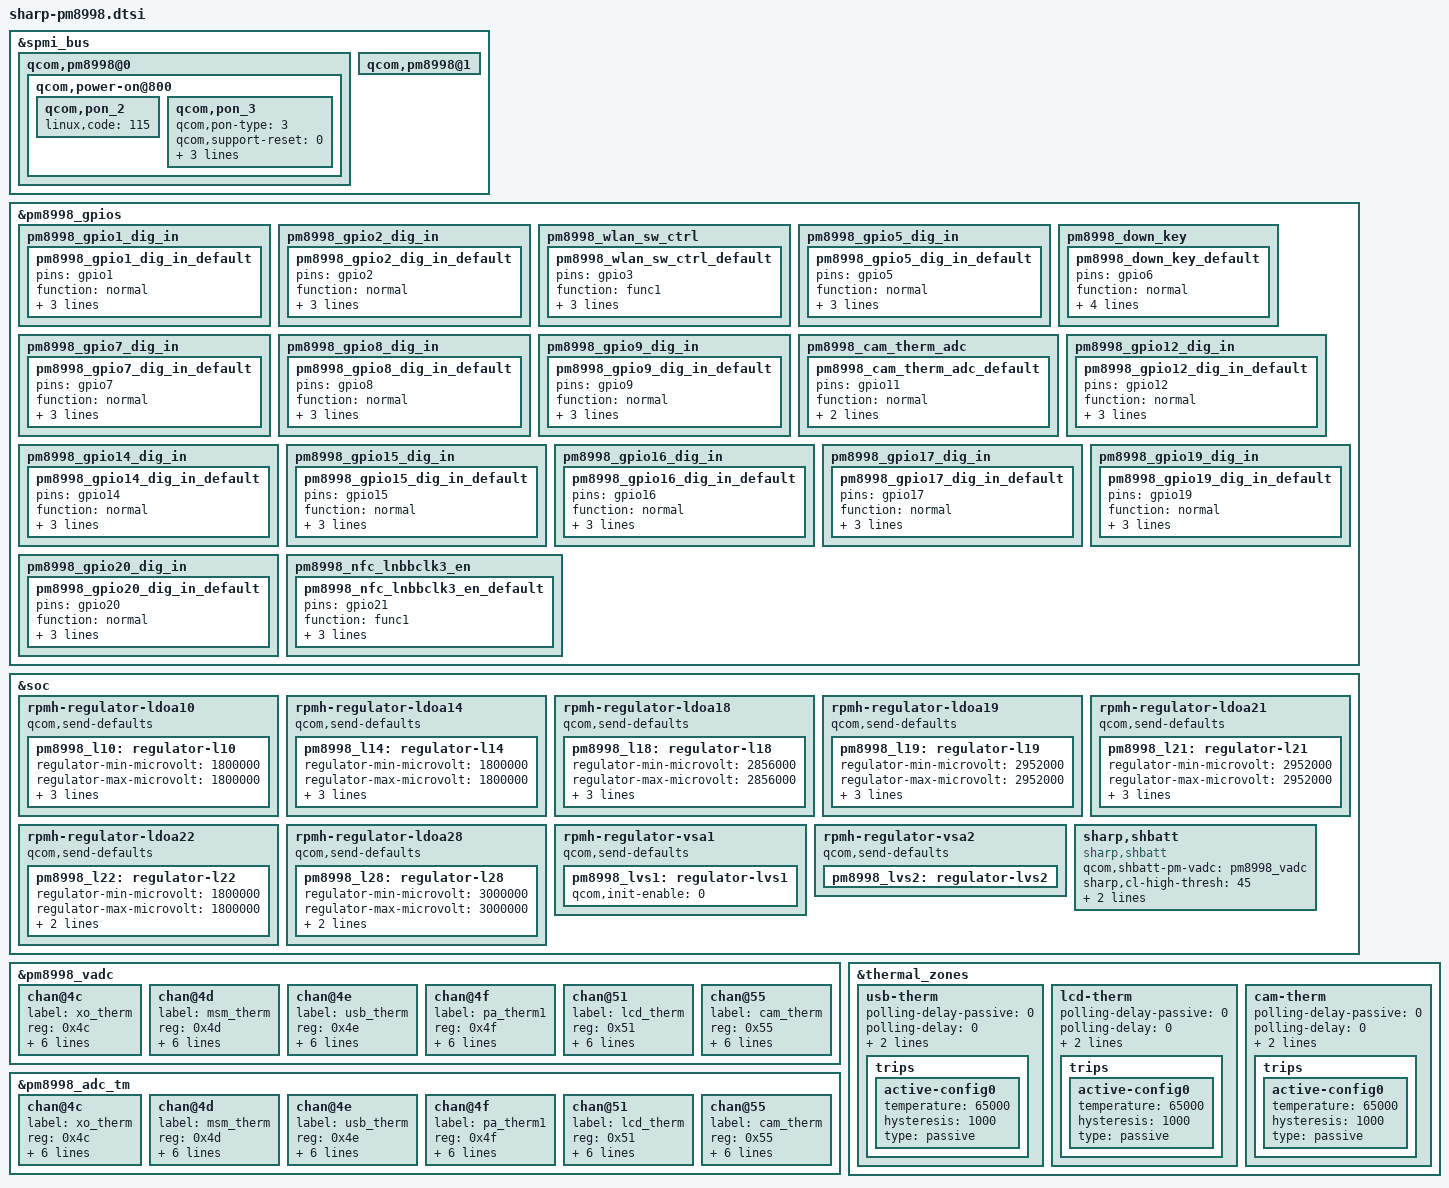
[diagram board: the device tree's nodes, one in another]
/* Copyright (c) 2014-2015, The Linux Foundation. All rights reserved.
 *
 * This program is free software; you can redistribute it and/or modify
 * it under the terms of the GNU General Public License version 2 and
 * only version 2 as published by the Free Software Foundation.
 *
 * This program is distributed in the hope that it will be useful,
 * but WITHOUT ANY WARRANTY; without even the implied warranty of
 * MERCHANTABILITY or FITNESS FOR A PARTICULAR PURPOSE.  See the
 * GNU General Public License for more details.
 */
#include <dt-bindings/gpio/gpio.h>
#include <dt-bindings/regulator/qcom,rpmh-regulator.h>

/*****************************************/
/*  pm8998: qcom,pm8998 alias            */
/*****************************************/

&spmi_bus {
	qcom,pm8998@0 {
		qcom,power-on@800 {
			qcom,pon_2 {
				linux,code = <115>;
			};
			qcom,pon_3 {
				qcom,pon-type = <3>;
				qcom,support-reset = <0>;
				qcom,pull-up = <1>;
				qcom,s1-timer = <6720>;
				qcom,s2-timer = <2000>;
			};
		};
	};

	qcom,pm8998@1 {
	};
};

/*****************************************/
/*  pm8998-gpios: qpnp-pin               */
/*****************************************/

&pm8998_gpios {
//	compatible = "qcom,spmi-gpio";
//	reg = <0xc000 0x1a00>;
//	interrupts = <0x0 0xc0 0 IRQ_TYPE_NONE>,
//			<0x0 0xc1 0 IRQ_TYPE_NONE>,
//			<0x0 0xc2 0 IRQ_TYPE_NONE>,
//			<0x0 0xc3 0 IRQ_TYPE_NONE>,
//			<0x0 0xc4 0 IRQ_TYPE_NONE>,
//			<0x0 0xc5 0 IRQ_TYPE_NONE>,
//			<0x0 0xc6 0 IRQ_TYPE_NONE>,
//			<0x0 0xc7 0 IRQ_TYPE_NONE>,
//			<0x0 0xc8 0 IRQ_TYPE_NONE>,
//			<0x0 0xc9 0 IRQ_TYPE_NONE>,
//			<0x0 0xca 0 IRQ_TYPE_NONE>,
//			<0x0 0xcb 0 IRQ_TYPE_NONE>,
//			<0x0 0xcc 0 IRQ_TYPE_NONE>,
//			<0x0 0xcd 0 IRQ_TYPE_NONE>,
//			<0x0 0xce 0 IRQ_TYPE_NONE>,
//			<0x0 0xcf 0 IRQ_TYPE_NONE>,
//			<0x0 0xd0 0 IRQ_TYPE_NONE>,
//			<0x0 0xd1 0 IRQ_TYPE_NONE>,
//			<0x0 0xd2 0 IRQ_TYPE_NONE>,
//			<0x0 0xd3 0 IRQ_TYPE_NONE>,
//			<0x0 0xd4 0 IRQ_TYPE_NONE>,
//			<0x0 0xd5 0 IRQ_TYPE_NONE>,
//			<0x0 0xd6 0 IRQ_TYPE_NONE>;
//	interrupt-names = "pm8998_gpio1", "pm8998_gpio2",
//			"pm8998_gpio3", "pm8998_gpio4",
//			"pm8998_gpio5", "pm8998_gpio6",
//			"pm8998_gpio7", "pm8998_gpio8",
//			"pm8998_gpio9", "pm8998_gpio10",
//			"pm8998_gpio11", "pm8998_gpio12",
//			"pm8998_gpio13", "pm8998_gpio14",
//			"pm8998_gpio15", "pm8998_gpio16",
//			"pm8998_gpio17", "pm8998_gpio18",
//			"pm8998_gpio19", "pm8998_gpio20",
//			"pm8998_gpio21", "pm8998_gpio22",
//			"pm8998_gpio23";
//	gpio-controller;
//	#gpio-cells = <2>;
//	qcom,gpios-disallowed = <24 25 26>;

//	pinctrl-names = "default";
//	pinctrl-0 = <&pm8998_gpio1_dig_in_default
//				&pm8998_gpio2_dig_in_default
//				&pm8998_wlan_sw_ctrl_default
//				&pm8998_gpio5_dig_in_default
//				&pm8998_down_key_default
//				&pm8998_gpio7_dig_in_default
//				&pm8998_gpio8_dig_in_default
//				&pm8998_gpio9_dig_in_default
//				&pm8998_sd_pow_en_default
//				&pm8998_cam_therm_adc_default
//				&pm8998_gpio12_dig_in_default
//				&pm8998_lcd_clk_default
//				&pm8998_gpio14_dig_in_default
//				&pm8998_gpio15_dig_in_default
//				&pm8998_gpio16_dig_in_default
//				&pm8998_gpio17_dig_in_default
//				&pm8998_gpio18_dig_in_default
//				&pm8998_gpio19_dig_in_default
//				&pm8998_gpio20_dig_in_default
//				&pm8998_nfc_lnbbclk3_en_default
//				&pm8998_gpio22_dig_in_default>;

	pm8998_gpio1_dig_in {
		/* I/PD/L */	/* - */
		pm8998_gpio1_dig_in_default: pm8998_gpio1_dig_in_default {
			pins = "gpio1";			/* GPIO 1 */
			function = "normal";	/* normal input */
			bias-pull-down;			/* pull down */
			power-source = <0>;		/* VIN0 */
			input-enable;			/* digital input */
		};
	};

	pm8998_gpio2_dig_in {
		/* I/PD/L */	/* - */
		pm8998_gpio2_dig_in_default: pm8998_gpio2_dig_in_default {
			pins = "gpio2";			/* GPIO 2 */
			function = "normal";	/* normal input */
			bias-pull-down;			/* pull down */
			power-source = <0>;		/* VIN0 */
			input-enable;			/* digital input */
		};
	};

	pm8998_wlan_sw_ctrl {
		/* I/PD/L */	/* WLAN_SW_CTRL */
		pm8998_wlan_sw_ctrl_default: pm8998_wlan_sw_ctrl_default {
			pins = "gpio3";			/* GPIO 3 */
			function = "func1";		/* Special Function 1 */
			bias-pull-down;			/* pull down */
			power-source = <0>;		/* VIN0 */
			input-enable;			/* digital input */
		};
	};

	pm8998_gpio5_dig_in {
		/* I/PD/L */	/* - */
		pm8998_gpio5_dig_in_default: pm8998_gpio5_dig_in_default {
			pins = "gpio5";			/* GPIO 5 */
			function = "normal";	/* normal input */
			bias-pull-down;			/* pull down */
			power-source = <0>;		/* VIN0 */
			input-enable;			/* digital input */
		};
	};

	pm8998_down_key {
		/* I/PU,30uA/H */	/* DOWN_KEY */
		pm8998_down_key_default: pm8998_down_key_default {
			pins = "gpio6";					/* GPIO 6 */
			function = "normal";			/* normal input */
			bias-pull-up;					/* enable pull up */
			qcom,pull-up-strength = <0>;	/* 30uA pull up */
			power-source = <0>;				/* VIN0 */
			input-enable;					/* digital input */
		};
	};

	pm8998_gpio7_dig_in {
		/* I/PD/L */	/* - */
		pm8998_gpio7_dig_in_default: pm8998_gpio7_dig_in_default {
			pins = "gpio7";			/* GPIO 7 */
			function = "normal";	/* normal input */
			bias-pull-down;			/* pull down */
			power-source = <0>;		/* VIN0 */
			input-enable;			/* digital input */
		};
	};

	pm8998_gpio8_dig_in {
		/* I/PD/L */	/* - */
		pm8998_gpio8_dig_in_default: pm8998_gpio8_dig_in_default {
			pins = "gpio8";			/* GPIO 8 */
			function = "normal";	/* normal input */
			bias-pull-down;			/* pull down */
			power-source = <0>;		/* VIN0 */
			input-enable;			/* digital input */
		};
	};

	pm8998_gpio9_dig_in {
		/* I/PD/L */	/* - */
		pm8998_gpio9_dig_in_default: pm8998_gpio9_dig_in_default {
			pins = "gpio9";			/* GPIO 9 */
			function = "normal";	/* normal input */
			bias-pull-down;			/* pull down */
			power-source = <0>;		/* VIN0 */
			input-enable;			/* digital input */
		};
	};

	pm8998_cam_therm_adc {
		/* I/-/Z */	/* CAM_THERM */
		pm8998_cam_therm_adc_default: pm8998_cam_therm_adc_default {
			pins = "gpio11";		/* GPIO 11 */
			function = "normal";	/* normal */
			bias-high-impedance;	/* DISABLE GPIO11 for ADC*/
			qcom,drive-strength = <1>;	/* Low strength */
		};
	};

	pm8998_gpio12_dig_in {
		/* I/PD/L */	/* - */
		pm8998_gpio12_dig_in_default: pm8998_gpio12_dig_in_default {
			pins = "gpio12";		/* GPIO 12 */
			function = "normal";	/* normal input */
			bias-pull-down;			/* pull down */
			power-source = <0>;		/* VIN0 */
			input-enable;			/* digital input */
		};
	};

	pm8998_gpio14_dig_in {
		/* I/PD/L */	/* - */
		pm8998_gpio14_dig_in_default: pm8998_gpio14_dig_in_default {
			pins = "gpio14";		/* GPIO 14 */
			function = "normal";	/* normal input */
			bias-pull-down;			/* pull down */
			power-source = <0>;		/* VIN0 */
			input-enable;			/* digital input */
		};
	};

	pm8998_gpio15_dig_in {
		/* I/PD/L */	/* - */
		pm8998_gpio15_dig_in_default: pm8998_gpio15_dig_in_default {
			pins = "gpio15";		/* GPIO 15 */
			function = "normal";	/* normal input */
			bias-pull-down;			/* pull down */
			power-source = <0>;		/* VIN0 */
			input-enable;			/* digital input */
		};
	};

	pm8998_gpio16_dig_in {
		/* I/PD/L */	/* - */
		pm8998_gpio16_dig_in_default: pm8998_gpio16_dig_in_default {
			pins = "gpio16";		/* GPIO 16 */
			function = "normal";	/* normal input */
			bias-pull-down;			/* pull down */
			power-source = <0>;		/* VIN0 */
			input-enable;			/* digital input */
		};
	};

	pm8998_gpio17_dig_in {
		/* I/PD/L */	/* - */
		pm8998_gpio17_dig_in_default: pm8998_gpio17_dig_in_default {
			pins = "gpio17";		/* GPIO 17 */
			function = "normal";	/* normal input */
			bias-pull-down;			/* pull down */
			power-source = <0>;		/* VIN0 */
			input-enable;			/* digital input */
		};
	};

	pm8998_gpio19_dig_in {
		/* I/PD/L */	/* - */
		pm8998_gpio19_dig_in_default: pm8998_gpio19_dig_in_default {
			pins = "gpio19";		/* GPIO 19 */
			function = "normal";	/* normal input */
			bias-pull-down;			/* pull down */
			power-source = <1>;		/* VIN1 */
			input-enable;			/* digital input */
		};
	};

	pm8998_gpio20_dig_in {
		/* I/PD/L */	/* - */
		pm8998_gpio20_dig_in_default: pm8998_gpio20_dig_in_default {
			pins = "gpio20";		/* GPIO 20 */
			function = "normal";	/* normal input */
			bias-pull-down;			/* pull down */
			power-source = <1>;		/* VIN1 */
			input-enable;			/* digital input */
		};
	};

	pm8998_nfc_lnbbclk3_en {
		/* I/NP/L */	/* NFC_LNBBCLK3_EN */
		pm8998_nfc_lnbbclk3_en_default: pm8998_nfc_lnbbclk3_en_default {
			pins = "gpio21";		/* GPIO 21 */
			function = "func1";		/* Special Function 1 */
			bias-pull-down;			/* pull down */
			power-source = <1>;		/* VIN1 */
			input-enable;			/* digital input */
		};
	};
};

/*****************************************/
/*  pm8998: rpm-regulator              */
/*****************************************/
&soc {
	rpmh-regulator-ldoa10 {
		qcom,send-defaults;
		pm8998_l10: regulator-l10 {	/* SIM2 */
			regulator-min-microvolt = <1800000>;
			regulator-max-microvolt = <1800000>;
			qcom,init-voltage = <1800000>;
			qcom,init-mode = <RPMH_REGULATOR_MODE_LPM>;
			qcom,init-enable = <0>;
		};
	};

	rpmh-regulator-ldoa14 {
		qcom,send-defaults;
		pm8998_l14: regulator-l14 {	/* LCD driver digital */
			regulator-min-microvolt = <1800000>;
			regulator-max-microvolt = <1800000>;
			qcom,init-voltage = <1800000>;
			qcom,init-mode = <RPMH_REGULATOR_MODE_HPM>;
			qcom,init-enable = <1>;
		};
	};

	rpmh-regulator-ldoa18 {
		qcom,send-defaults;
		pm8998_l18: regulator-l18 {	/* DTV LNA */
			regulator-min-microvolt = <2856000>;
			regulator-max-microvolt = <2856000>;
			qcom,init-voltage = <2856000>;
			qcom,init-mode = <RPMH_REGULATOR_MODE_HPM>;
			qcom,init-enable = <0>;
		};
	};

	rpmh-regulator-ldoa19 {
		qcom,send-defaults;
		pm8998_l19: regulator-l19 {	/* Proximity */
			regulator-min-microvolt = <2952000>;
			regulator-max-microvolt = <2952000>;
			qcom,init-voltage = <2952000>;
			qcom,init-mode = <RPMH_REGULATOR_MODE_LPM>;
			qcom,init-enable = <0>;
		};
	};

	rpmh-regulator-ldoa21 {
		qcom,send-defaults;
		pm8998_l21: regulator-l21 {	/* Camera AF driver */
			regulator-min-microvolt = <2952000>;
			regulator-max-microvolt = <2952000>;
			qcom,init-voltage = <2952000>;
			qcom,init-mode = <RPMH_REGULATOR_MODE_HPM>;
			qcom,init-enable = <0>;
		};
	};

	rpmh-regulator-ldoa22 {
//		qcom,use-awake-state;
		qcom,send-defaults;
		pm8998_l22: regulator-l22 {	/* Fingerprint */
			regulator-min-microvolt = <1800000>;
			regulator-max-microvolt = <1800000>;
			qcom,init-voltage = <1800000>;
			qcom,init-enable = <0>;
		};
	};

	rpmh-regulator-ldoa28 {
		qcom,send-defaults;
		pm8998_l28: regulator-l28 {	/* Touch panel analog */
			regulator-min-microvolt = <3000000>;
			regulator-max-microvolt = <3000000>;
			qcom,init-voltage = <3000000>;
			qcom,init-mode = <RPMH_REGULATOR_MODE_HPM>;
			/delete-property/ qcom,init-enable;
		};
	};

	rpmh-regulator-vsa1 {
		qcom,send-defaults;
		pm8998_lvs1: regulator-lvs1 {	/* Camera IO */
			qcom,init-enable = <0>;
		};
	};

	rpmh-regulator-vsa2 {
		qcom,send-defaults;
		pm8998_lvs2: regulator-lvs2 {	/* Touch panel digital and /IO */
			/delete-property/ qcom,init-enable;
		};
	};
};
/*****************************************/
/*  qpnp-adc-voltage                     */
/*****************************************/
&pm8998_vadc {
	chan@4c { /* xo_therm */
		label = "xo_therm";
		reg = <0x4c>;
		qcom,decimation = <2>;
		qcom,pre-div-channel-scaling = <0>;
		qcom,calibration-type = "ratiometric";
		qcom,scale-function = <4>;
		qcom,hw-settle-time = <2>;
		qcom,fast-avg-setup = <0>;
	};

	chan@4d { /* msm_therm */
		label = "msm_therm";
		reg = <0x4d>;
		qcom,decimation = <2>;
		qcom,pre-div-channel-scaling = <0>;
		qcom,calibration-type = "ratiometric";
		qcom,scale-function = <2>;
		qcom,hw-settle-time = <2>;
		qcom,fast-avg-setup = <0>;
	};

	chan@4e { /* usb_therm */
		label = "usb_therm";
		reg = <0x4e>;
		qcom,decimation = <2>;
		qcom,pre-div-channel-scaling = <0>;
		qcom,calibration-type = "ratiometric";
		qcom,scale-function = <2>;
		qcom,hw-settle-time = <2>;
		qcom,fast-avg-setup = <0>;
	};

	chan@4f { /* pa_therm1 */
		label = "pa_therm1";
		reg = <0x4f>;
		qcom,decimation = <2>;
		qcom,pre-div-channel-scaling = <0>;
		qcom,calibration-type = "ratiometric";
		qcom,scale-function = <2>;
		qcom,hw-settle-time = <2>;
		qcom,fast-avg-setup = <0>;
	};

	chan@51 { /* lcd_therm */
		label = "lcd_therm";
		reg = <0x51>;
		qcom,decimation = <2>;
		qcom,pre-div-channel-scaling = <0>;
		qcom,calibration-type = "ratiometric";
		qcom,scale-function = <2>;
		qcom,hw-settle-time = <2>;
		qcom,fast-avg-setup = <0>;
	};

	chan@55 { /* cam_therm */
		label = "cam_therm";
		reg = <0x55>;
		qcom,decimation = <2>;
		qcom,pre-div-channel-scaling = <0>;
		qcom,calibration-type = "ratiometric";
		qcom,scale-function = <2>;
		qcom,hw-settle-time = <2>;
		qcom,fast-avg-setup = <0>;
	};
};

/*****************************************/
/*  qpnp-vadc-tm                         */
/*****************************************/
&pm8998_adc_tm  {
	chan@4c { /* xo_therm */
		label = "xo_therm";
		reg = <0x4c>;
		qcom,pre-div-channel-scaling = <0>;
		qcom,calibration-type = "ratiometric";
		qcom,scale-function = <4>;
		qcom,hw-settle-time = <2>;
		qcom,btm-channel-number = <0x68>;	/* M1_ADC_CH_SEL_CTL */
		qcom,thermal-node;
	};

	chan@4d { /* msm_therm */
		label = "msm_therm";
		reg = <0x4d>;
		qcom,pre-div-channel-scaling = <0>;
		qcom,calibration-type = "ratiometric";
		qcom,scale-function = <2>;
		qcom,hw-settle-time = <2>;
		qcom,btm-channel-number = <0x70>;	/* M2_ADC_CH_SEL_CTL */
		qcom,thermal-node;
	};

	chan@4e { /* usb_therm */
		label = "usb_therm";
		reg = <0x4e>;
		qcom,pre-div-channel-scaling = <0>;
		qcom,calibration-type = "ratiometric";
		qcom,scale-function = <2>;
		qcom,hw-settle-time = <2>;
		qcom,btm-channel-number = <0x88>;	/* M5_ADC_CH_SEL_CTL */
		qcom,thermal-node;
	};

	chan@4f { /* pa_therm1 */
		label = "pa_therm1";
		reg = <0x4f>;
		qcom,pre-div-channel-scaling = <0>;
		qcom,calibration-type = "ratiometric";
		qcom,scale-function = <2>;
		qcom,hw-settle-time = <2>;
		qcom,btm-channel-number = <0x78>;	/* M3_ADC_CH_SEL_CTL */
		qcom,thermal-node;
	};

	chan@51 { /* quiet_therm -> lcd_therm */
		label = "lcd_therm";
		reg = <0x51>;
		qcom,pre-div-channel-scaling = <0>;
		qcom,calibration-type = "ratiometric";
		qcom,scale-function = <2>;
		qcom,hw-settle-time = <2>;
		qcom,btm-channel-number = <0x80>;	/* M4_ADC_CH_SEL_CTL */
		qcom,thermal-node;
	};

	chan@55 { /* cam_therm */
		label = "cam_therm";
		reg = <0x55>;
		qcom,pre-div-channel-scaling = <0>;
		qcom,calibration-type = "ratiometric";
		qcom,scale-function = <2>;
		qcom,hw-settle-time = <2>;
		qcom,btm-channel-number = <0x98>;	/* M7_ADC_CH_SEL_CTL */
		qcom,thermal-node;
	};
};

/*****************************************/
/*  thermal_zones                        */
/*****************************************/
&thermal_zones {
	usb-therm {
		polling-delay-passive = <0>;
		polling-delay = <0>;
		thermal-sensors = <&pm8998_adc_tm 0x4e>;
		thermal-governor = "user_space";

		trips {
			active-config0 {
				temperature = <65000>;
				hysteresis = <1000>;
				type = "passive";
			};
		};
	};

	lcd-therm {
		polling-delay-passive = <0>;
		polling-delay = <0>;
		thermal-sensors = <&pm8998_adc_tm 0x51>;
		thermal-governor = "user_space";

		trips {
			active-config0 {
				temperature = <65000>;
				hysteresis = <1000>;
				type = "passive";
			};
		};
	};

	cam-therm {
		polling-delay-passive = <0>;
		polling-delay = <0>;
		thermal-sensors = <&pm8998_adc_tm 0x55>;
		thermal-governor = "user_space";

		trips {
			active-config0 {
				temperature = <65000>;
				hysteresis = <1000>;
				type = "passive";
			};
		};
	};
};

/*****************************************/
/*  SHARP Device Drivers                 */
/*****************************************/
&soc {
	/*---------------------------------------*/
	/*  Battery Control Driver               */
	/*---------------------------------------*/
	sharp,shbatt {
		compatible = "sharp,shbatt";
		qcom,shbatt-pm-vadc = <&pm8998_vadc>;
		sharp,cl-high-thresh = <45>;
		sharp,cl-low-thresh = <45>;
		sharp,pa_temp_label = "pa_therm1";
		status = "ok";
	};
};
